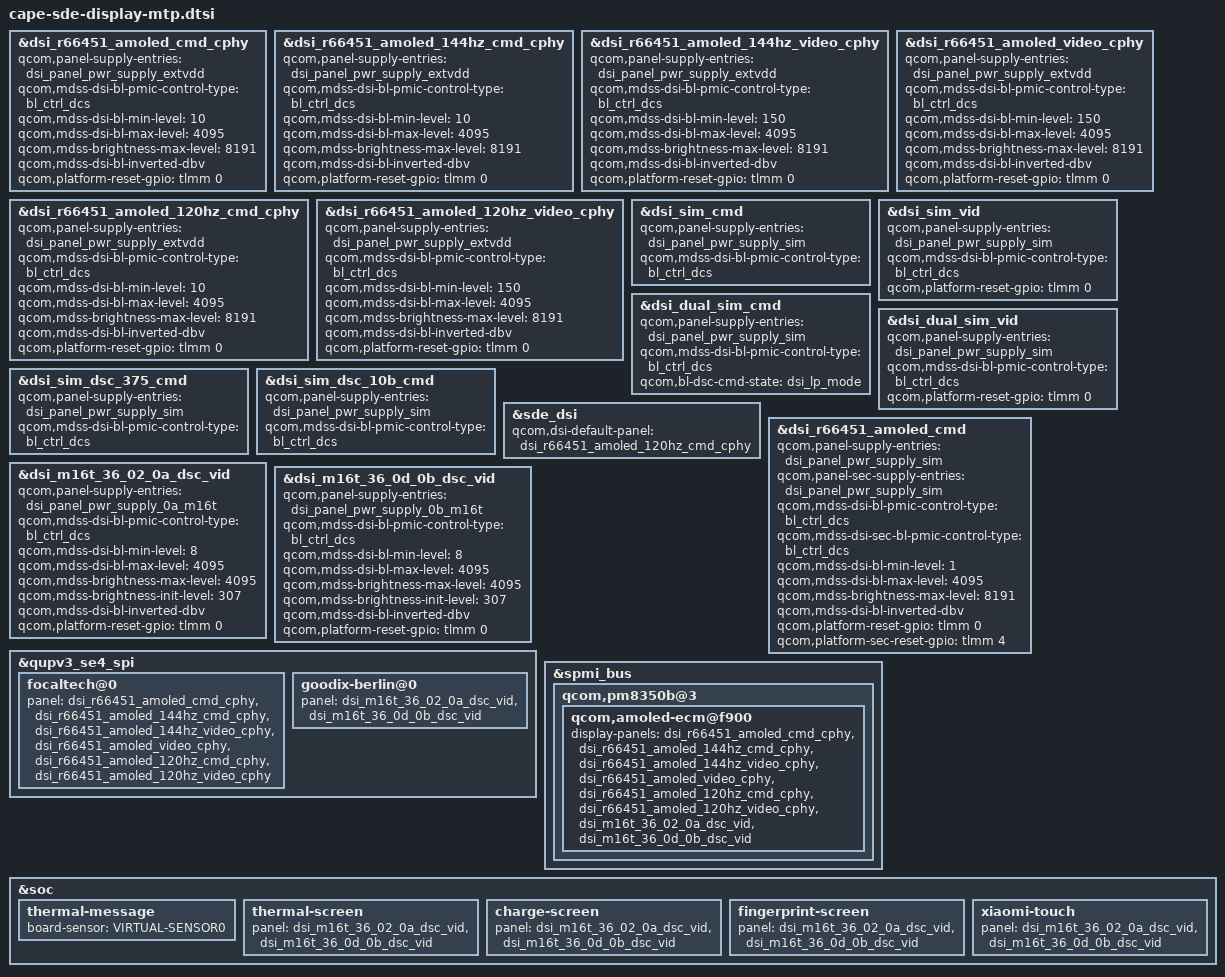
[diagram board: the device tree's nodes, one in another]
#include "cape-sde-display.dtsi"

&dsi_r66451_amoled_cmd_cphy {
	qcom,panel-supply-entries = <&dsi_panel_pwr_supply_extvdd>;
	qcom,mdss-dsi-bl-pmic-control-type = "bl_ctrl_dcs";
	qcom,mdss-dsi-bl-min-level = <10>;
	qcom,mdss-dsi-bl-max-level = <4095>;
	qcom,mdss-brightness-max-level = <8191>;
	qcom,mdss-dsi-bl-inverted-dbv;
	qcom,platform-reset-gpio = <&tlmm 0 0>;
};

&dsi_r66451_amoled_144hz_cmd_cphy {
	qcom,panel-supply-entries = <&dsi_panel_pwr_supply_extvdd>;
	qcom,mdss-dsi-bl-pmic-control-type = "bl_ctrl_dcs";
	qcom,mdss-dsi-bl-min-level = <10>;
	qcom,mdss-dsi-bl-max-level = <4095>;
	qcom,mdss-brightness-max-level = <8191>;
	qcom,mdss-dsi-bl-inverted-dbv;
	qcom,platform-reset-gpio = <&tlmm 0 0>;
};

&dsi_r66451_amoled_144hz_video_cphy {
	qcom,panel-supply-entries = <&dsi_panel_pwr_supply_extvdd>;
	qcom,mdss-dsi-bl-pmic-control-type = "bl_ctrl_dcs";
	qcom,mdss-dsi-bl-min-level = <150>;
	qcom,mdss-dsi-bl-max-level = <4095>;
	qcom,mdss-brightness-max-level = <8191>;
	qcom,mdss-dsi-bl-inverted-dbv;
	qcom,platform-reset-gpio = <&tlmm 0 0>;
};

&dsi_r66451_amoled_video_cphy {
	qcom,panel-supply-entries = <&dsi_panel_pwr_supply_extvdd>;
	qcom,mdss-dsi-bl-pmic-control-type = "bl_ctrl_dcs";
	qcom,mdss-dsi-bl-min-level = <150>;
	qcom,mdss-dsi-bl-max-level = <4095>;
	qcom,mdss-brightness-max-level = <8191>;
	qcom,mdss-dsi-bl-inverted-dbv;
	qcom,platform-reset-gpio = <&tlmm 0 0>;
};

&dsi_r66451_amoled_120hz_cmd_cphy {
	qcom,panel-supply-entries = <&dsi_panel_pwr_supply_extvdd>;
	qcom,mdss-dsi-bl-pmic-control-type = "bl_ctrl_dcs";
	qcom,mdss-dsi-bl-min-level = <10>;
	qcom,mdss-dsi-bl-max-level = <4095>;
	qcom,mdss-brightness-max-level = <8191>;
	qcom,mdss-dsi-bl-inverted-dbv;
	qcom,platform-reset-gpio = <&tlmm 0 0>;
};

&dsi_r66451_amoled_120hz_video_cphy {
	qcom,panel-supply-entries = <&dsi_panel_pwr_supply_extvdd>;
	qcom,mdss-dsi-bl-pmic-control-type = "bl_ctrl_dcs";
	qcom,mdss-dsi-bl-min-level = <150>;
	qcom,mdss-dsi-bl-max-level = <4095>;
	qcom,mdss-brightness-max-level = <8191>;
	qcom,mdss-dsi-bl-inverted-dbv;
	qcom,platform-reset-gpio = <&tlmm 0 0>;
};

&dsi_sim_cmd {
	qcom,panel-supply-entries = <&dsi_panel_pwr_supply_sim>;
	qcom,mdss-dsi-bl-pmic-control-type = "bl_ctrl_dcs";
};

&dsi_sim_vid {
	qcom,panel-supply-entries = <&dsi_panel_pwr_supply_sim>;
	qcom,mdss-dsi-bl-pmic-control-type = "bl_ctrl_dcs";
	qcom,platform-reset-gpio = <&tlmm 0 0>;
};

&dsi_dual_sim_cmd {
	qcom,panel-supply-entries = <&dsi_panel_pwr_supply_sim>;
	qcom,mdss-dsi-bl-pmic-control-type = "bl_ctrl_dcs";
	qcom,bl-dsc-cmd-state = "dsi_lp_mode";
};

&dsi_dual_sim_vid {
	qcom,panel-supply-entries = <&dsi_panel_pwr_supply_sim>;
	qcom,mdss-dsi-bl-pmic-control-type = "bl_ctrl_dcs";
	qcom,platform-reset-gpio = <&tlmm 0 0>;
};

&dsi_sim_dsc_375_cmd {
	qcom,panel-supply-entries = <&dsi_panel_pwr_supply_sim>;
	qcom,mdss-dsi-bl-pmic-control-type = "bl_ctrl_dcs";
};

&dsi_sim_dsc_10b_cmd {
	qcom,panel-supply-entries = <&dsi_panel_pwr_supply_sim>;
	qcom,mdss-dsi-bl-pmic-control-type = "bl_ctrl_dcs";
};

&sde_dsi {
	qcom,dsi-default-panel = <&dsi_r66451_amoled_120hz_cmd_cphy>;
};

&dsi_r66451_amoled_cmd {
	qcom,panel-supply-entries = <&dsi_panel_pwr_supply_sim>;
	qcom,panel-sec-supply-entries = <&dsi_panel_pwr_supply_sim>;
	qcom,mdss-dsi-bl-pmic-control-type = "bl_ctrl_dcs";
	qcom,mdss-dsi-sec-bl-pmic-control-type = "bl_ctrl_dcs";
	qcom,mdss-dsi-bl-min-level = <1>;
	qcom,mdss-dsi-bl-max-level = <4095>;
	qcom,mdss-brightness-max-level = <8191>;
	qcom,mdss-dsi-bl-inverted-dbv;
	qcom,platform-reset-gpio = <&tlmm 0 0>;
	qcom,platform-sec-reset-gpio = <&tlmm 4 0>;
};

&dsi_m16t_36_02_0a_dsc_vid {
	qcom,panel-supply-entries = <&dsi_panel_pwr_supply_0a_m16t>;
	qcom,mdss-dsi-bl-pmic-control-type = "bl_ctrl_dcs";
	qcom,mdss-dsi-bl-min-level = <8>;
	qcom,mdss-dsi-bl-max-level = <4095>;
	qcom,mdss-brightness-max-level = <4095>;
	qcom,mdss-brightness-init-level = <307>;
	qcom,mdss-dsi-bl-inverted-dbv;
	qcom,platform-reset-gpio = <&tlmm 0 0>;
};

&dsi_m16t_36_0d_0b_dsc_vid {
	qcom,panel-supply-entries = <&dsi_panel_pwr_supply_0b_m16t>;
	qcom,mdss-dsi-bl-pmic-control-type = "bl_ctrl_dcs";
	qcom,mdss-dsi-bl-min-level = <8>;
	qcom,mdss-dsi-bl-max-level = <4095>;
	qcom,mdss-brightness-max-level = <4095>;
	qcom,mdss-brightness-init-level = <307>;
	qcom,mdss-dsi-bl-inverted-dbv;
	qcom,platform-reset-gpio = <&tlmm 0 0>;
};

&qupv3_se4_spi {
	focaltech@0 {
		panel = <&dsi_r66451_amoled_cmd_cphy
			&dsi_r66451_amoled_144hz_cmd_cphy
			&dsi_r66451_amoled_144hz_video_cphy
			&dsi_r66451_amoled_video_cphy
			&dsi_r66451_amoled_120hz_cmd_cphy
			&dsi_r66451_amoled_120hz_video_cphy>;
	};

	goodix-berlin@0 {
		panel = <&dsi_m16t_36_02_0a_dsc_vid
			&dsi_m16t_36_0d_0b_dsc_vid>;
	};
};

&spmi_bus {
	qcom,pm8350b@3 {
		qcom,amoled-ecm@f900 {
			display-panels = <&dsi_r66451_amoled_cmd_cphy
					&dsi_r66451_amoled_144hz_cmd_cphy
					&dsi_r66451_amoled_144hz_video_cphy
					&dsi_r66451_amoled_video_cphy
					&dsi_r66451_amoled_120hz_cmd_cphy
					&dsi_r66451_amoled_120hz_video_cphy
					&dsi_m16t_36_02_0a_dsc_vid
					&dsi_m16t_36_0d_0b_dsc_vid>;
		};
	};
};

&soc {
	thermal-message {
		board-sensor = "VIRTUAL-SENSOR0";
	};

	thermal-screen {
		panel = <&dsi_m16t_36_02_0a_dsc_vid &dsi_m16t_36_0d_0b_dsc_vid>;
	};

	charge-screen {
		panel = <&dsi_m16t_36_02_0a_dsc_vid &dsi_m16t_36_0d_0b_dsc_vid>;
	};

	fingerprint-screen {
		panel = <&dsi_m16t_36_02_0a_dsc_vid &dsi_m16t_36_0d_0b_dsc_vid>;
	};

	xiaomi-touch {
		panel = <&dsi_m16t_36_02_0a_dsc_vid &dsi_m16t_36_0d_0b_dsc_vid>;
	};
};
